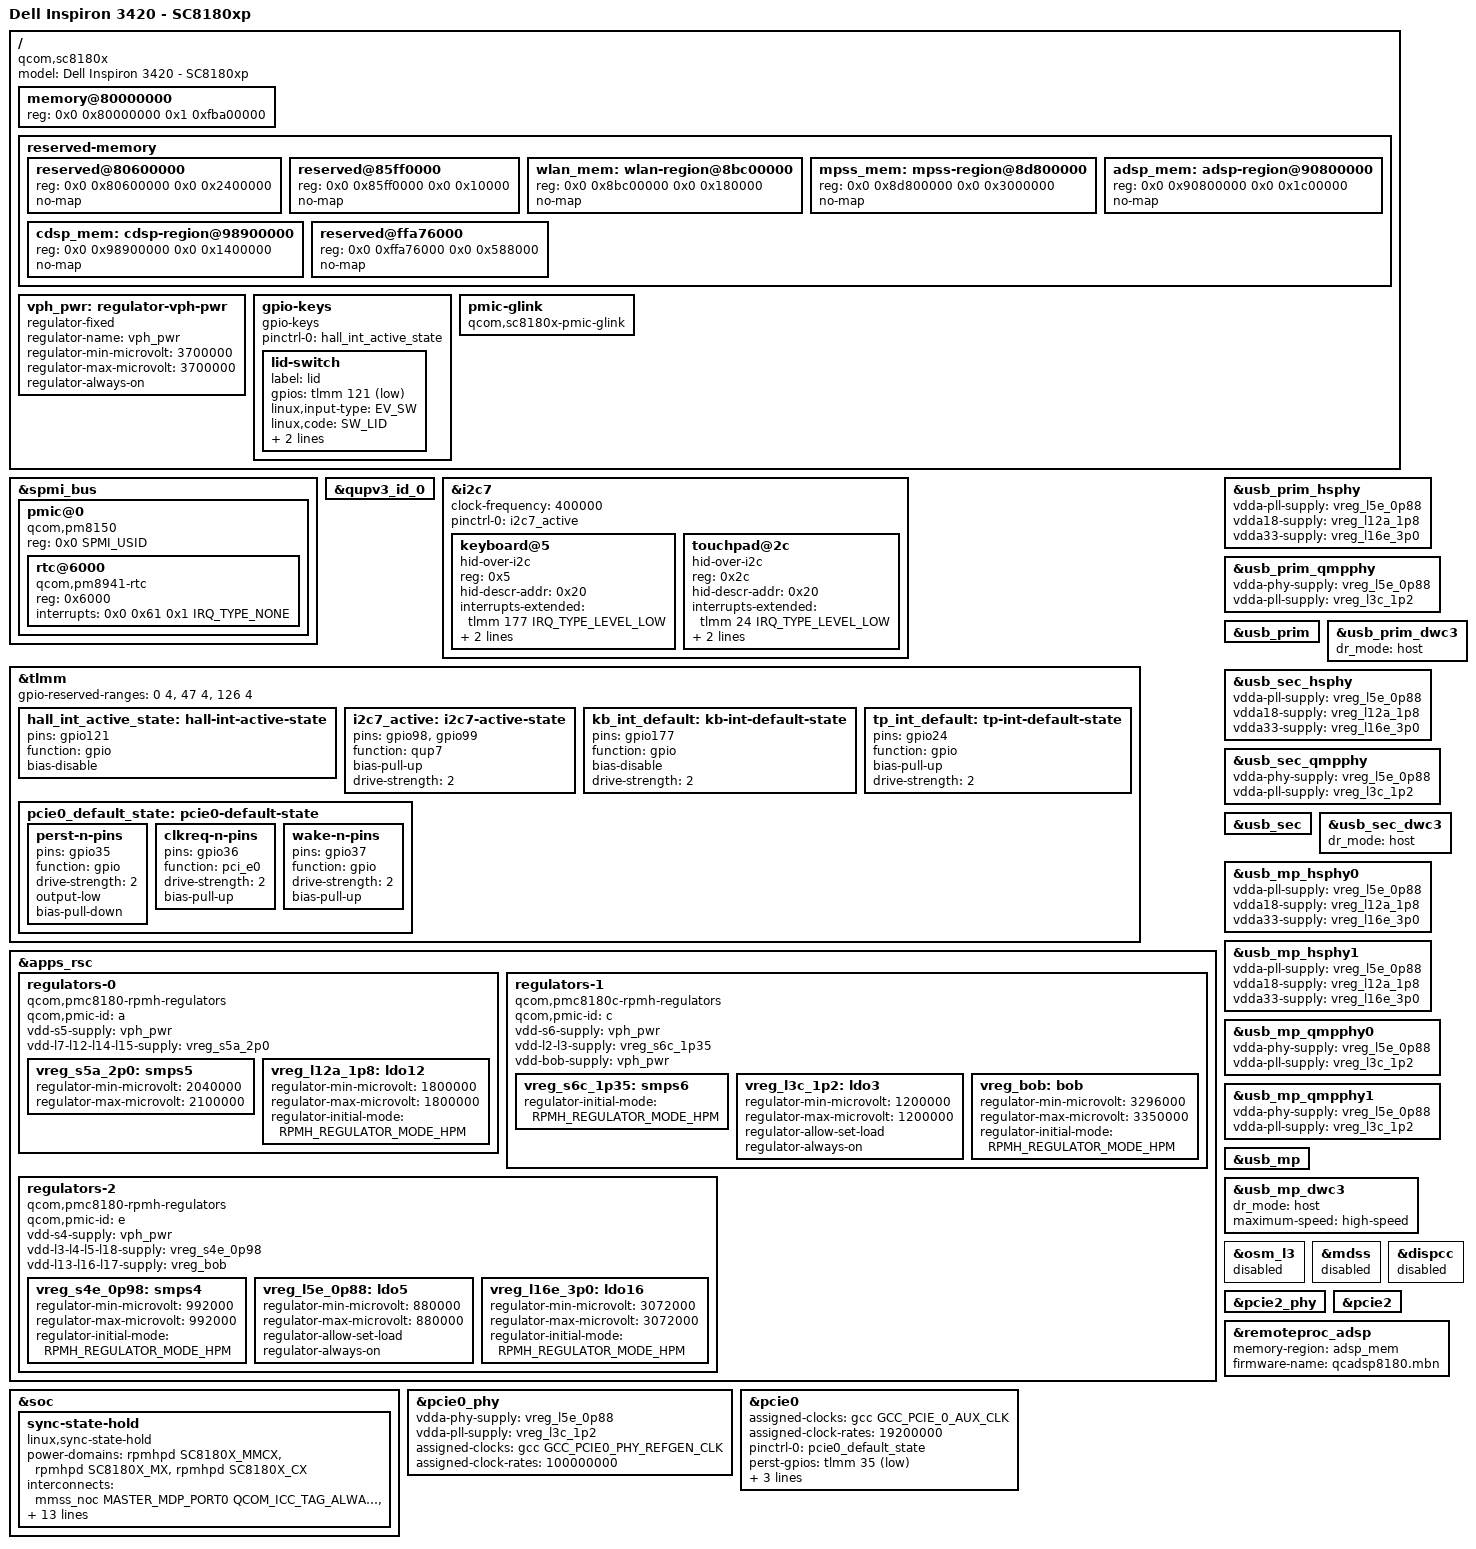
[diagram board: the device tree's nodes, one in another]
// SPDX-License-Identifier: BSD-3-Clause
/*
 * SC8180X laptop ("QCOMM SDM8180" DSDT) - memory map, lid switch (LID0),
 * touchpad (TCPD) and keyboard (ECSH).
 *
 * Sources:
 *   - GRUB `lsmmap` photo (UEFI memory map)  -> memory@80000000, reserved-memory
 *   - dsdt.dsl                               -> LID0 / TCPD / ECSH / I2C8
 *
 * Built on top of mainline arch/arm64/boot/dts/qcom/sc8180x.dtsi.
 */

/dts-v1/;

#include <dt-bindings/gpio/gpio.h>
#include <dt-bindings/input/gpio-keys.h>
#include <dt-bindings/input/input.h>
#include <dt-bindings/interrupt-controller/irq.h>
#include <dt-bindings/regulator/qcom,rpmh-regulator.h>
#include <dt-bindings/spmi/spmi.h>
#include <dt-bindings/interrupt-controller/irq.h>

#include "sc8180x.dtsi"

/*
 * EFI map: RAM at 0x80000000-0x27ba00000.  Mainline reservations at
 * 0x9d400000 and 0x9f800000 are KEPT even though UEFI reports them as
 * available: they are likely firmware/secure memory (safer to leave reserved).
 */

/ {
	model = "Dell Inspiron 3420 - SC8180xp";
	compatible = "qcom,sc8180x";

	/* EFI: 0x80000000 + 0x1fba00000 = 0x27ba00000 (~7.9 GiB usable) */
	memory@80000000 {
		device_type = "memory";
		reg = <0x0 0x80000000 0x1 0xfba00000>;
	};

	reserved-memory {
		/* EFI "reserved RAM" 0x80600000 len 0x2400000 */
		reserved@80600000 {
			reg = <0x0 0x80600000 0x0 0x2400000>;
			no-map;
		};

		/* EFI "reserved RAM" 0x85ff0000 len 0x10000 */
		reserved@85ff0000 {
			reg = <0x0 0x85ff0000 0x0 0x10000>;
			no-map;
		};

		/*
		 * EFI "reserved RAM" 0x8b700000 len 0xf400000 (to 0x9ab00000).
		 * UEFI only shows the whole span; the split into remoteproc
		 * regions is borrowed from sc8180x-lenovo-flex-5g.dts.
		 */
		wlan_mem: wlan-region@8bc00000 {
			reg = <0x0 0x8bc00000 0x0 0x180000>;
			no-map;
		};

		mpss_mem: mpss-region@8d800000 {
			reg = <0x0 0x8d800000 0x0 0x3000000>;
			no-map;
		};

		adsp_mem: adsp-region@90800000 {
			reg = <0x0 0x90800000 0x0 0x1c00000>;
			no-map;
		};

		cdsp_mem: cdsp-region@98900000 {
			reg = <0x0 0x98900000 0x0 0x1400000>;
			no-map;
		};

		/*
		 * UEFI runtime/ACPI span, contiguous in the map:
		 *   0xffa76000 +0x190000  firmware code
		 *   0xffc06000 +0x2bc000  reserved
		 *   0xffec2000 +0x10000   reserved
		 *   0xffed2000 +0x50000   ACPI NVS
		 *   0xfff22000 +0xdc000   ACPI reclaimable
		 * Only needed for a DT-only boot; harmless under EFI.
		 */
		reserved@ffa76000 {
			reg = <0x0 0xffa76000 0x0 0x588000>;
			no-map;
		};
	};

	vph_pwr: regulator-vph-pwr {
		compatible = "regulator-fixed";
		regulator-name = "vph_pwr";
		regulator-min-microvolt = <3700000>;
		regulator-max-microvolt = <3700000>;
		regulator-always-on;
	};

	/* \_SB.LID0 (PNP0C0D); state read from GpioIo pin 0x79 (\_SB.GIO0.LIDR) */
	gpio-keys {
		compatible = "gpio-keys";

		pinctrl-0 = <&hall_int_active_state>;
		pinctrl-names = "default";

		lid-switch {
			label = "lid";
			gpios = <&tlmm 121 GPIO_ACTIVE_LOW>;	/* high = open */
			linux,input-type = <EV_SW>;
			linux,code = <SW_LID>;
			wakeup-source;				/* AEI event is wake-capable */
			wakeup-event-action = <EV_ACT_DEASSERTED>;
		};
	};
};

&spmi_bus {
	  pmic@0 {
	  	 compatible="qcom,spmi-pmic";
		 reg=<0x0 SPMI_USID>;
		 
		 };
};

&qupv3_id_0 {
	status = "okay";
};

/* ACPI \_SB.I2C8 (UID 8): MMIO 0x89c000, GSIV 640 (SPI 608) == mainline i2c7 */
&i2c7 {
	clock-frequency = <400000>;	/* I2cSerialBus ConnectionSpeed 0x61a80 */

	pinctrl-0 = <&i2c7_active>;
	pinctrl-names = "default";

	status = "okay";

	/* \_SB.I2C8.ECSH: HID "ENES6243", I2C addr 0x05 */
	keyboard@5 {
		compatible = "hid-over-i2c";
		reg = <0x5>;
		hid-descr-addr = <0x20>;		/* _DSM function 1 */

		/* GpioInt pin 0xb1, level, active-low, wake-capable */
		interrupts-extended = <&tlmm 177 IRQ_TYPE_LEVEL_LOW>;
		wakeup-source;

		pinctrl-0 = <&kb_int_default>;
		pinctrl-names = "default";
	};

	/* \_SB.I2C8.TCPD: HID 27C60002 (TPVF=1) or 06CB0002 (TPVF=2), addr 0x2c */
	touchpad@2c {
		compatible = "hid-over-i2c";
		reg = <0x2c>;
		hid-descr-addr = <0x20>;		/* _DSM function 1 */

		/*
		 * FIXME: DSDT GpioInt pin is 0x280 (640), outside the TLMM range
		 * (0-189).  GPIO 24 is the upstream Lenovo Flex 5G value, not
		 * taken from this DSDT - verify on hardware.
		 */
		interrupts-extended = <&tlmm 24 IRQ_TYPE_LEVEL_LOW>;
		wakeup-source;

		pinctrl-0 = <&tp_int_default>;
		pinctrl-names = "default";
	};
};

&tlmm {
	gpio-reserved-ranges = <0 4>, <47 4>, <126 4>;

	hall_int_active_state: hall-int-active-state {
		pins = "gpio121";
		function = "gpio";
		bias-disable;			/* GpioIo PullNone */
	};

	/* pinmux is not in the DSDT (firmware sets it); values from upstream */
	i2c7_active: i2c7-active-state {
		pins = "gpio98", "gpio99";
		function = "qup7";
		bias-pull-up;
		drive-strength = <2>;
	};

	kb_int_default: kb-int-default-state {
		pins = "gpio177";
		function = "gpio";
		bias-disable;			/* PullDefault in DSDT */
		drive-strength = <2>;
	};

	tp_int_default: tp-int-default-state {
		pins = "gpio24";
		function = "gpio";
		bias-pull-up;			/* GpioInt PullUp */
		drive-strength = <2>;
	};
	pcie0_default_state: pcie0-default-state {
		perst-n-pins {
			pins = "gpio35";
			function = "gpio";
			drive-strength= <2>;
			output-low;
			bias-pull-down;
		};
		clkreq-n-pins {
			pins = "gpio36";
			function = "pci_e0";
			drive-strength = <2>;
			bias-pull-up;
		};
		wake-n-pins {
			pins = "gpio37";
			function = "gpio";
			drive-strength = <2>;
			bias-pull-up;
		};
	};
};

/*
 * RPMh regulators needed by the USB PHYs.  Not in the DSDT (Windows manages
 * them through PEP0); values taken from sc8180x-lenovo-flex-5g.dts.
 */
&apps_rsc {
	regulators-0 {
		compatible = "qcom,pmc8180-rpmh-regulators";
		qcom,pmic-id = "a";

		vdd-s5-supply = <&vph_pwr>;
		vdd-l7-l12-l14-l15-supply = <&vreg_s5a_2p0>;

		vreg_s5a_2p0: smps5 {
			regulator-min-microvolt = <2040000>;
			regulator-max-microvolt = <2100000>;
		};

		vreg_l12a_1p8: ldo12 {
			regulator-min-microvolt = <1800000>;
			regulator-max-microvolt = <1800000>;
			regulator-initial-mode = <RPMH_REGULATOR_MODE_HPM>;
		};
	};

	regulators-1 {
		compatible = "qcom,pmc8180c-rpmh-regulators";
		qcom,pmic-id = "c";

		vdd-s6-supply = <&vph_pwr>;
		vdd-l2-l3-supply = <&vreg_s6c_1p35>;
		vdd-bob-supply = <&vph_pwr>;

		vreg_s6c_1p35: smps6 {
			//regulator-min-microvolt = <1350000>;
			//regulator-max-microvolt = <1372000>;
			regulator-initial-mode = <RPMH_REGULATOR_MODE_HPM>;
		};

		vreg_l3c_1p2: ldo3 {
			regulator-min-microvolt = <1200000>;
			regulator-max-microvolt = <1200000>;
			regulator-allow-set-load;
			regulator-always-on;
		};

		vreg_bob: bob {
			regulator-min-microvolt = <3296000>;
			regulator-max-microvolt = <3350000>;
			regulator-initial-mode = <RPMH_REGULATOR_MODE_HPM>;
		};
	};

	regulators-2 {
		compatible = "qcom,pmc8180-rpmh-regulators";
		qcom,pmic-id = "e";

		vdd-s4-supply = <&vph_pwr>;
		vdd-l3-l4-l5-l18-supply = <&vreg_s4e_0p98>;
		vdd-l13-l16-l17-supply = <&vreg_bob>;

		vreg_s4e_0p98: smps4 {
			regulator-min-microvolt = <992000>;
			regulator-max-microvolt = <992000>;
			regulator-initial-mode = <RPMH_REGULATOR_MODE_HPM>;
		};

		vreg_l5e_0p88: ldo5 {
			regulator-min-microvolt = <880000>;
			regulator-max-microvolt = <880000>;
			regulator-allow-set-load;
			regulator-always-on;
		};

		vreg_l16e_3p0: ldo16 {
			regulator-min-microvolt = <3072000>;
			regulator-max-microvolt = <3072000>;
			regulator-initial-mode = <RPMH_REGULATOR_MODE_HPM>;
		};
	};
};

/*
 * USB.  DSDT: URS0 @0x0a600000 = usb_prim, URS1 @0x0a800000 = usb_sec,
 * USB2 @0x0a400000 = usb_mp (2 ports).  Host mode only; the Type-C
 * (pmic_glink/UCSI) orientation switching is omitted, so SuperSpeed works
 * in one cable orientation only - high-speed works in both.
 */
&usb_prim_hsphy {
	vdda-pll-supply = <&vreg_l5e_0p88>;
	vdda18-supply = <&vreg_l12a_1p8>;
	vdda33-supply = <&vreg_l16e_3p0>;

	status = "okay";
};

&usb_prim_qmpphy {
	vdda-phy-supply = <&vreg_l5e_0p88>;
	vdda-pll-supply = <&vreg_l3c_1p2>;

	status = "okay";
};

&usb_prim {
	status = "okay";
};

&usb_prim_dwc3 {
	dr_mode = "host";
};

&usb_sec_hsphy {
	vdda-pll-supply = <&vreg_l5e_0p88>;
	vdda18-supply = <&vreg_l12a_1p8>;
	vdda33-supply = <&vreg_l16e_3p0>;

	status = "okay";
};

&usb_sec_qmpphy {
	vdda-phy-supply = <&vreg_l5e_0p88>;
	vdda-pll-supply = <&vreg_l3c_1p2>;

	status = "okay";
};

&usb_sec {
	status = "okay";
};

&usb_sec_dwc3 {
	dr_mode = "host";
};

&usb_mp_hsphy0 {
	vdda-pll-supply = <&vreg_l5e_0p88>;
	vdda18-supply = <&vreg_l12a_1p8>;
	vdda33-supply = <&vreg_l16e_3p0>;

	status = "okay";
};

&usb_mp_hsphy1 {
	vdda-pll-supply = <&vreg_l5e_0p88>;
	vdda18-supply = <&vreg_l12a_1p8>;
	vdda33-supply = <&vreg_l16e_3p0>;

	status = "okay";
};

&usb_mp_qmpphy0 {
	vdda-phy-supply = <&vreg_l5e_0p88>;
	vdda-pll-supply = <&vreg_l3c_1p2>;

	status = "okay";
};

&usb_mp_qmpphy1 {
	vdda-phy-supply = <&vreg_l5e_0p88>;
	vdda-pll-supply = <&vreg_l3c_1p2>;

	status = "okay";
};

&usb_mp {
	status = "okay";
};

&usb_mp_dwc3 {
	dr_mode = "host";
};

&usb_mp_hsphy0 {
	       status = "okay";
	       };
&usb_mp_hsphy1 {
status = "okay";
};

&usb_mp_qmpphy0 {
status = "okay";
};
&usb_mp_qmpphy1 {
status = "okay";
};

&osm_l3 {
status="disabled";
};


&soc {
	sync-state-hold {
		compatible = "linux,sync-state-hold";

		/* rpmhpd provider: MMCX (display), MX, CX */
		power-domains = <&rpmhpd SC8180X_MMCX>,
				<&rpmhpd SC8180X_MX>,
				<&rpmhpd SC8180X_CX>;

		/* one path per interconnect provider */
		interconnects =
			<&mmss_noc MASTER_MDP_PORT0 QCOM_ICC_TAG_ALWAYS
			 &mc_virt SLAVE_EBI_CH0 QCOM_ICC_TAG_ALWAYS>,
			<&gem_noc MASTER_AMPSS_M0 QCOM_ICC_TAG_ACTIVE_ONLY
			 &mc_virt SLAVE_EBI_CH0 QCOM_ICC_TAG_ACTIVE_ONLY>,
			<&aggre1_noc MASTER_QUP_0 QCOM_ICC_TAG_ACTIVE_ONLY
			 &mc_virt SLAVE_EBI_CH0 QCOM_ICC_TAG_ACTIVE_ONLY>,
			<&aggre2_noc MASTER_USB3 QCOM_ICC_TAG_ACTIVE_ONLY
			 &mc_virt SLAVE_EBI_CH0 QCOM_ICC_TAG_ACTIVE_ONLY>,
			<&system_noc 0 QCOM_ICC_TAG_ACTIVE_ONLY
			 &mc_virt SLAVE_EBI_CH0 QCOM_ICC_TAG_ACTIVE_ONLY>,
			<&config_noc 0 QCOM_ICC_TAG_ACTIVE_ONLY
			 &mc_virt SLAVE_EBI_CH0 QCOM_ICC_TAG_ACTIVE_ONLY>,
			<&compute_noc 0 QCOM_ICC_TAG_ACTIVE_ONLY
			 &mc_virt SLAVE_EBI_CH0 QCOM_ICC_TAG_ACTIVE_ONLY>;
	};
};

&mdss {
  status="disabled";
};
&dispcc {
  status="disabled";
};
&usb_mp_dwc3 {
	     dr_mode = "host";
	     maximum-speed = "high-speed";
};

&pcie0_phy {
    vdda-phy-supply = <&vreg_l5e_0p88>;
    vdda-pll-supply = <&vreg_l3c_1p2>;

    assigned-clocks = <&gcc GCC_PCIE0_PHY_REFGEN_CLK>;
    assigned-clock-rates = <100000000>;

    status = "okay";
};

&pcie0 {
    assigned-clocks = <&gcc GCC_PCIE_0_AUX_CLK>;
    assigned-clock-rates = <19200000>;
    pinctrl-names = "default";
    pinctrl-0 = <&pcie0_default_state>;
    perst-gpios = <&tlmm 35 GPIO_ACTIVE_LOW>;
    wake-gpios = <&tlmm 37 GPIO_ACTIVE_LOW>;
    vdda-supply=<&vreg_l5e_0p88>;
    vddpe-3v3-supply=<&vreg_bob>;
    status = "okay";
};

&pcie2_phy {
	   status="okay";
	   };
&pcie2 {
       status = "okay";
       };

&remoteproc_adsp {
   memory-region = <&adsp_mem>;
   firmware-name= "qcadsp8180.mbn";
   status="okay";
};

&spmi_bus {
   pmic@0 {
   	  compatible = "qcom,pm8150", "qcom,spmi-pmic";
	  reg = <0x0 SPMI_USID>;
	  rtc@6000 {
	  	   compatible = "qcom,pm8941-rtc";
		   reg=<0x6000>;
		   reg-names="rtc","alarm";
		   interrupts=<0x0 0x61 0x1 IRQ_TYPE_NONE>;
		   };
	};
};

/ {
    pmic-glink {
    	       compatible="qcom,sc8180x-pmic-glink",
	       "qcom,pmic-glink";
	       };
  };
